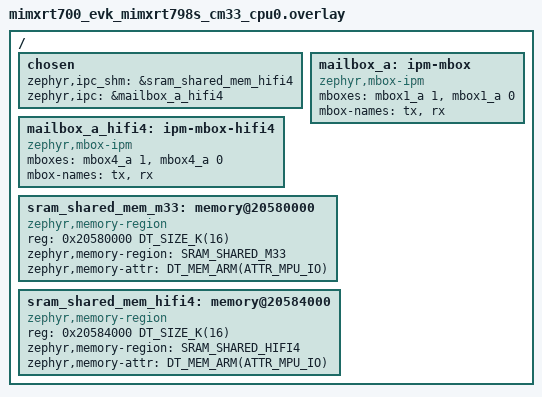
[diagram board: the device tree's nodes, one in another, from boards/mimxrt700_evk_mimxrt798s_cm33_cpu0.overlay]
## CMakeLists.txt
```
# Copyright 2023-2026 NXP
#
# SPDX-License-Identifier: BSD-3-Clause

cmake_minimum_required(VERSION 3.20.0)

set(REMOTE_ZEPHYR_DIR ${CMAKE_CURRENT_BINARY_DIR}/../remote/zephyr)

find_package(Zephyr REQUIRED HINTS $ENV{ZEPHYR_BASE})
project(rpmsglite_pingpong)

message(STATUS "${BOARD} compile as Main Core in this sample")

if(CONFIG_INCLUDE_REMOTE_DIR)
  target_include_directories(zephyr_interface
    INTERFACE ${REMOTE_ZEPHYR_DIR}/include/public)
endif()

enable_language(C ASM)

target_sources(app PRIVATE src/main.c)

target_include_directories(app PRIVATE ${CMAKE_CURRENT_SOURCE_DIR})

# Also include this directory into rpmsg_lite library because of project specific include rpsmg_config.h
target_include_directories(rpmsg_lite PRIVATE ${CMAKE_CURRENT_SOURCE_DIR})

if (CONFIG_BOARD_MIMXRT685_EVK OR CONFIG_BOARD_MIMXRT700_EVK)
    include("${ZEPHYR_BASE}/samples/boards/nxp/adsp/rtxxx/common/dsp-load.cmake")
endif()
```

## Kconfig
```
# Copyright 2023-2026 NXP
#
# SPDX-License-Identifier: BSD-3-Clause

source "Kconfig.zephyr"

config INCLUDE_REMOTE_DIR
	bool "Include remote core header directory"
	help
	  Include remote build header files. Can be used if primary image
	  needs to be aware of size or base address of secondary image

config RPMSG_LITE_ENABLE_CACHE
    bool "Enable cache for RPMsg Lite"
    default n
    help
      Enable cache support for RPMsg Lite communication.
```

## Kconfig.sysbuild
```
# Copyright 2023-2026 NXP
#
# SPDX-License-Identifier: BSD-3-Clause

source "share/sysbuild/Kconfig"

config RPMSG_LITE_REMOTE_BOARD
string
    default "mimxrt1170_evkb/mimxrt1176/cm4" if $(BOARD) = "mimxrt1170_evkb"
	default "mimxrt1170_evk/mimxrt1176/cm4" if $(BOARD) = "mimxrt1170_evk"
	default "mimxrt1160_evk/mimxrt1166/cm4" if $(BOARD) = "mimxrt1160_evk"
	default "lpcxpresso55s69/lpc55s69/cpu1" if $(BOARD) = "lpcxpresso55s69"
    default "lpcxpresso54114/lpc54114/m0" if $(BOARD) = "lpcxpresso54114"
    default "mimxrt685_evk/mimxrt685s/hifi4" if $(BOARD) = "mimxrt685_evk"
    default "mimxrt700_evk/mimxrt798s/hifi4" if $(BOARD) = "mimxrt700_evk"
    default "mps3/an524/cpu1" if $(BOARD) = "mps3"
```

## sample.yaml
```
sample:
  description: RPMSG-Lite Ping Pong sample
  name: rpmsglite pingpong
tests:
  sample.ipc.rpmsglite_pingpong:
    platform_allow:
      - mps3/an524/cpu0
      - mimxrt1170_evk@B/mimxrt1176/cm7
      - mimxrt1170_evk/mimxrt1176/cm7
      - mimxrt1160_evk/mimxrt1166/cm7
      - lpcxpresso55s69/lpc55s69/cpu0
      - lpcxpresso54114/lpc54114/m4
    integration_platforms:
      - mimxrt1170_evk/mimxrt1176/cm7
    tags: ipm
    harness: console
    sysbuild: true
    harness_config:
      type: multi_line
      regex:
        - "Primary core received a msg"
        - "Message: Size=4, DATA = 1"
        - "Primary core received a msg"
        - "Message: Size=4, DATA = 101"
        - "RPMsg demo ends"
```

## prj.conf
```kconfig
CONFIG_IPM=y
CONFIG_EVENTS=y
CONFIG_PRINTK=y
CONFIG_RPMSGLITE=y
CONFIG_TIMESLICE_SIZE=1
CONFIG_MAIN_STACK_SIZE=2048
CONFIG_HEAP_MEM_POOL_SIZE=4096

# Uncomment for Debugging Support
# CONFIG_INIT_STACKS=y
# CONFIG_NO_OPTIMIZATIONS=y
# CONFIG_DEBUG_THREAD_INFO=y
# CONFIG_THREAD_STACK_INFO=y
```

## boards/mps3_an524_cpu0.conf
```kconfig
# Copyright 2026 Arm Limited and/or its affiliates <open-source-office@arm.com>
#
# SPDX-License-Identifier: BSD-3-Clause

CONFIG_IPM=y
CONFIG_EVENTS=y
CONFIG_PRINTK=y
CONFIG_RPMSGLITE=y
CONFIG_TIMESLICE_SIZE=1
CONFIG_MAIN_STACK_SIZE=2048
CONFIG_HEAP_MEM_POOL_SIZE=4096
```

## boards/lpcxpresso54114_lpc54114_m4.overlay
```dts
/*
 * Copyright (c) 2019 Linaro Limited
 * Copyright 2023 NXP
 *
 * SPDX-License-Identifier: BSD-3-Clause
 */

/ {
	chosen {
		/*
		 * shared memory reserved for the inter-processor communication
		 */
		zephyr,ipc_shm = &sramx1;
		zephyr,ipc = &mailbox0;
	};

	sramx1:memory@4000000{
		compatible = "mmio-sram";
		reg = <0x4000000 0x8000>;
	};
};
```

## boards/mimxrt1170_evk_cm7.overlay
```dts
/*
 * Copyright 2023 NXP
 *
 * SPDX-License-Identifier: Apache-2.0
 */

#include <zephyr/dt-bindings/memory-attr/memory-attr-arm.h>

/ {
	chosen {
		zephyr,ipc_shm = &ocram2_overlay;
	};

	/* OpenAMP fails with full 512K OCRAM2 memory region as shared memory.
	 * Define a subset of the OCRAM2 region for demo to use
	 * Note that shared memory must have specific MPU attributes set
	 */
	ocram2_overlay: memory@202c0000 {
		compatible = "zephyr,memory-region", "mmio-sram";
		reg = <0x202c0000 DT_SIZE_K(16)>;
		zephyr,memory-region="OCRAM2_OVERLAY";
		zephyr,memory-attr = <( DT_MEM_ARM(ATTR_MPU_IO) )>;
	};
};
```

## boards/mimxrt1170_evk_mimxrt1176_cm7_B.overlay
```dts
/*
 * Copyright 2023 NXP
 *
 * SPDX-License-Identifier: BSD-3-Clause
 */

#include <zephyr/dt-bindings/memory-attr/memory-attr-arm.h>

/ {
	chosen {
		zephyr,ipc_shm = &ocram2_overlay;
	};

	/* OpenAMP fails with full 512K OCRAM2 memory region as shared memory.
	 * Define a subset of the OCRAM2 region for demo to use
	 * Note that shared memory must have specific MPU attributes set
	 */
	ocram2_overlay: memory@202c0000 {
		compatible = "zephyr,memory-region", "mmio-sram";
		reg = <0x202c0000 DT_SIZE_K(16)>;
		zephyr,memory-region="OCRAM2_OVERLAY";
		zephyr,memory-attr = <( DT_MEM_ARM(ATTR_MPU_IO) )>;
	};
};
```

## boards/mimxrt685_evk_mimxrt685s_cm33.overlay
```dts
/*
 * Copyright 2026 NXP
 *
 * SPDX-License-Identifier: Apache-2.0
 */

#include <zephyr/dt-bindings/ipc_service/static_vrings.h>
#include <zephyr/dt-bindings/memory-attr/memory-attr-arm.h>

#include <nxp/nxp_rt6xx_hifi4memsplit.dtsi>

&dsp {
	status = "okay";
};

/ {
	chosen {
		/*
		 * shared memory reserved for the inter-processor communication
		 */

		zephyr,ipc_shm = &sram_sh_mem;
		zephyr,ipc = &mailbox_a;
	};

	/* Define memory regions for IPC */
	sram_sh_mem: memory@20070000 {
		compatible = "zephyr,memory-region", "mmio-sram";
		reg = <0x20070000 DT_SIZE_K(32)>;
		zephyr,memory-region = "SRAM_SH_MEM";
		zephyr,memory-attr = <DT_MEM_ARM(ATTR_MPU_IO)>;
	};

	mailbox_a: ipm-mbox {
		compatible = "zephyr,mbox-ipm";
		mboxes = <&mbox 1>, <&mbox 0>;
		mbox-names = "tx", "rx";
	};
};
```

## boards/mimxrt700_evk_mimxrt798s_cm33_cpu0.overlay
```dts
/*
 * Copyright 2026 NXP
 *
 * SPDX-License-Identifier: Apache-2.0
 */

#include <zephyr/dt-bindings/ipc_service/static_vrings.h>
#include <zephyr/dt-bindings/memory-attr/memory-attr-arm.h>

/ {
	chosen {
		zephyr,ipc_shm = &sram_shared_mem_hifi4;
		zephyr,ipc = &mailbox_a_hifi4;
	};

	mailbox_a: ipm-mbox {
		compatible = "zephyr,mbox-ipm";
		mboxes = <&mbox1_a 1>, <&mbox1_a 0>;
		mbox-names = "tx", "rx";
	};

    mailbox_a_hifi4: ipm-mbox-hifi4 {
		compatible = "zephyr,mbox-ipm";
		mboxes = <&mbox4_a 1>, <&mbox4_a 0>;
		mbox-names = "tx", "rx";
	};

	/* Define memory regions */
	sram_shared_mem_m33: memory@20580000 {
		compatible = "zephyr,memory-region", "mmio-sram";
		reg = <0x20580000 DT_SIZE_K(16)>;
		zephyr,memory-region = "SRAM_SHARED_M33";
		zephyr,memory-attr = <DT_MEM_ARM(ATTR_MPU_IO)>;
	};

    sram_shared_mem_hifi4: memory@20584000 {
		compatible = "zephyr,memory-region", "mmio-sram";
		reg = <0x20584000 DT_SIZE_K(16)>;
		zephyr,memory-region = "SRAM_SHARED_HIFI4";
		zephyr,memory-attr = <DT_MEM_ARM(ATTR_MPU_IO)>;
	};
};
```

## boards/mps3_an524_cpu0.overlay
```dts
/*
 * Copyright 2026 Arm Limited and/or its affiliates <open-source-office@arm.com>
 *
 * SPDX-License-Identifier: BSD-3-Clause
 */

/ {
	chosen {
		/*
		 * shared memory reserved for the inter-processor communication
		 */
		zephyr,ipc_shm = &sramx;
		zephyr,ipc = &mhu0;
	};

	/* top 32 KB of the BRAM, non-secure alias */
	sramx: memory@28078000 {
		compatible = "mmio-sram";
		reg = <0x28078000 0x8000>;
	};
};
```

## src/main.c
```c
/*
 * Copyright 2023-2026 NXP
 *
 * SPDX-License-Identifier: BSD-3-Clause
 */

#include <zephyr/drivers/ipm.h>
#include <zephyr/sys/printk.h>
#include <zephyr/device.h>
#include <stdio.h>
#include <stdlib.h>
#include <string.h>
#include <zephyr/init.h>

#include "common.h"
#include "rpmsg_lite.h"

#if defined(CONFIG_BOARD_MIMXRT685_EVK) || defined(CONFIG_BOARD_MIMXRT700_EVK)
#include "dsp.h"
#endif

#if defined(CONFIG_SOC_AN524)
#include <soc.h>
#endif

#define REMOTE_EPT_ADDR               (30U)
#define LOCAL_EPT_ADDR                (40U)
#define APP_RPMSG_READY_EVENT_DATA    (1U)
#define APP_RPMSG_EP_READY_EVENT_DATA (2U)

#define SHM_MEM_ADDR DT_REG_ADDR(DT_CHOSEN(zephyr_ipc_shm))
#define SHM_MEM_SIZE DT_REG_SIZE(DT_CHOSEN(zephyr_ipc_shm))

#define APP_THREAD_STACK_SIZE (1024)
K_THREAD_STACK_DEFINE(thread_stack, APP_THREAD_STACK_SIZE);
static struct k_thread thread_data;

struct rpmsg_lite_instance *gp_rpmsg_dev_inst;
struct rpmsg_lite_endpoint *gp_rpmsg_ept;
struct rpmsg_lite_instance g_rpmsg_ctxt;
struct rpmsg_lite_ept_static_context g_ept_context;
volatile int32_t g_has_received;

uint32_t *shared_memory = (uint32_t *)SHM_MEM_ADDR;

K_EVENT_DEFINE(wait_event);

typedef struct the_message
{
    uint32_t DATA;
} THE_MESSAGE, *THE_MESSAGE_PTR;

static THE_MESSAGE volatile g_msg = {0};

/* This is the read callback, note we are in a task context when this callback
is invoked, so kernel primitives can be used freely */
static int32_t rpmsg_ept_read_cb(void *payload, uint32_t payload_len, uint32_t src, void *priv)
{
    int32_t *has_received = priv;

    if (payload_len <= sizeof(THE_MESSAGE))
    {
        (void)memcpy((void *)&g_msg, payload, payload_len);
        *has_received = 1;
    }
    (void)printk("Primary core received a msg\r\n");
    (void)printk("Message: Size=%x, DATA = %i\r\n", payload_len, g_msg.DATA);
    return RL_RELEASE;
}

static void application_thread(void *arg1, void *arg2, void *arg3)
{
    ARG_UNUSED(arg1);
    ARG_UNUSED(arg2);
    ARG_UNUSED(arg3);

    gp_rpmsg_dev_inst =
        rpmsg_lite_master_init(shared_memory, SHM_MEM_SIZE, RPMSG_LITE_LINK_ID, RL_NO_FLAGS, &g_rpmsg_ctxt);

    gp_rpmsg_ept = rpmsg_lite_create_ept(gp_rpmsg_dev_inst, LOCAL_EPT_ADDR, rpmsg_ept_read_cb, (void *)&g_has_received,
                                         &g_ept_context);

#if defined(CONFIG_SOC_AN524)
    /* The remote image boots from QSPI XIP which is much slower than
     * the primary core startup. Send the first message with retries
     * until the remote replies (its reply means it is fully up).
     * rpmsg_lite_is_link_up() cannot be used for this purpose
     * because master_init() sets link_state=1 immediately. */
    g_msg.DATA = 0U;
    uint32_t retry_cnt = 0U;
    do
    {
        if (retry_cnt == 0U)
        {
            (void)k_event_wait_all(&wait_event, 5, false, K_SECONDS(2));
        }
        (void)rpmsg_lite_send(gp_rpmsg_dev_inst, gp_rpmsg_ept, REMOTE_EPT_ADDR, (char *)&g_msg, sizeof(THE_MESSAGE),
                              RL_DONT_BLOCK);
        for (uint32_t i = 0U; (g_has_received == 0) && (i < 5U); i++)
        {
            k_sleep(K_MSEC(200));
        }
        retry_cnt++;
    } while ((g_has_received == 0) && (retry_cnt < 50U));
#else
    /* Temporary wait a bit here until remote core will process initialization and is ready to receive data */
    (void)k_event_wait_all(&wait_event, 5, false, K_MSEC(50));

    /* Send the first message to the remoteproc */
    g_msg.DATA = 0U;
    (void)rpmsg_lite_send(gp_rpmsg_dev_inst, gp_rpmsg_ept, REMOTE_EPT_ADDR, (char *)&g_msg, sizeof(THE_MESSAGE),
                          RL_DONT_BLOCK);
#endif

    while (g_msg.DATA <= 100U)
    {
        if (1 == g_has_received)
        {
            g_has_received = 0;
            g_msg.DATA++;
            (void)rpmsg_lite_send(gp_rpmsg_dev_inst, gp_rpmsg_ept, REMOTE_EPT_ADDR, (char *)&g_msg, sizeof(THE_MESSAGE),
                                  RL_DONT_BLOCK);
        }
    }

    (void)rpmsg_lite_destroy_ept(gp_rpmsg_dev_inst, gp_rpmsg_ept);
    gp_rpmsg_ept = ((void *)0);
    (void)rpmsg_lite_deinit(gp_rpmsg_dev_inst);

    /* Print the ending banner */
    (void)printk("\r\nRPMsg demo ends\r\n");
}

int main(void)
{
#if defined(CONFIG_BOARD_MIMXRT685_EVK) || defined(CONFIG_BOARD_MIMXRT700_EVK)
    dsp_start();
    k_sleep(K_MSEC(500));
#endif

    printk("Starting application thread on Main Core!\n");
    k_thread_create(&thread_data, thread_stack, APP_THREAD_STACK_SIZE, application_thread, NULL, NULL, NULL,
                    K_PRIO_COOP(7), 0, K_NO_WAIT);

#if defined(CONFIG_SOC_AN524)
    /* Release the secondary core held in reset on the SSE-200 */
    wakeup_cpu1();
#endif

    return 0;
}
```
